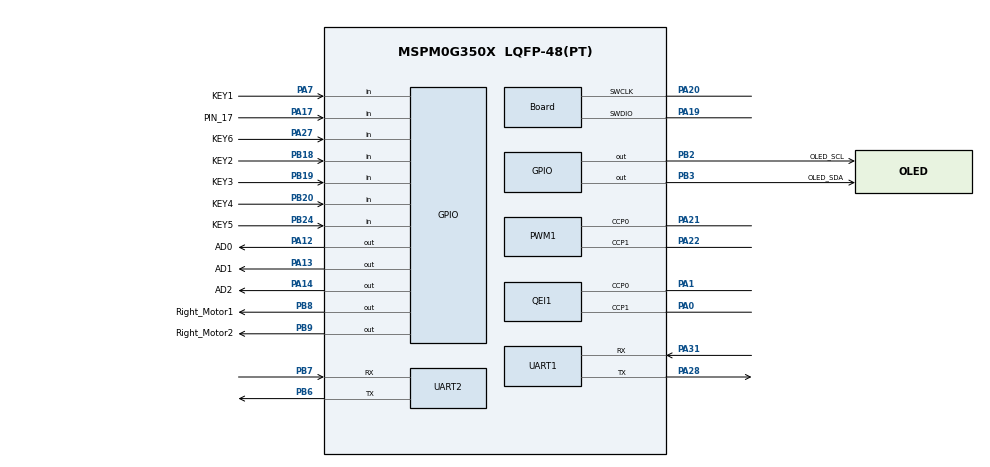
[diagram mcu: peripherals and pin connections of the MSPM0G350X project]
/**
 * @cliArgs --device "MSPM0G350X" --package "LQFP-48(PT)" --part "Default" --product "mspm0_sdk@1.30.00.03"
 * @versions {"tool":"1.19.0+3426"}
 */

/**
 * Import the modules used in this configuration.
 */
const ADC12         = scripting.addModule("/ti/driverlib/ADC12", {}, false);
const ADC121        = ADC12.addInstance();
const GPIO          = scripting.addModule("/ti/driverlib/GPIO", {}, false);
const GPIO1         = GPIO.addInstance();
const GPIO2         = GPIO.addInstance();
const GPIO3         = GPIO.addInstance();
const GPIO4         = GPIO.addInstance();
const GPIO5         = GPIO.addInstance();
const GPIO6         = GPIO.addInstance();
const PWM           = scripting.addModule("/ti/driverlib/PWM", {}, false);
const PWM1          = PWM.addInstance();
const QEI           = scripting.addModule("/ti/driverlib/QEI", {}, false);
const QEI1          = QEI.addInstance();
const SYSCTL        = scripting.addModule("/ti/driverlib/SYSCTL");
const SYSTICK       = scripting.addModule("/ti/driverlib/SYSTICK");
const TIMER         = scripting.addModule("/ti/driverlib/TIMER", {}, false);
const TIMER1        = TIMER.addInstance();
const UART          = scripting.addModule("/ti/driverlib/UART", {}, false);
const UART1         = UART.addInstance();
const UART2         = UART.addInstance();
const UART3         = UART.addInstance();
const UART4         = UART.addInstance();
const ProjectConfig = scripting.addModule("/ti/project_config/ProjectConfig");

/**
 * Write custom configuration values to the imported modules.
 */
const gate7  = system.clockTree["MFCLKGATE"];
gate7.enable = true;

ADC121.sampClkDiv                        = "DL_ADC12_CLOCK_DIVIDE_8";
ADC121.repeatMode                        = true;
ADC121.powerDownMode                     = "DL_ADC12_POWER_DOWN_MODE_MANUAL";
ADC121.$name                             = "ADC1";
ADC121.adcMem0_name                      = "ADC_Channel0";
ADC121.peripheral.$assign                = "ADC1";
ADC121.peripheral.adcPin0.$assign        = "PA15";
ADC121.adcPin0Config.hideOutputInversion = scripting.forceWrite(false);
ADC121.adcPin0Config.$name               = "ti_driverlib_gpio_GPIOPinGeneric2";

const Board                       = scripting.addModule("/ti/driverlib/Board", {}, false);
Board.peripheral.$assign          = "DEBUGSS";
Board.peripheral.swclkPin.$assign = "PA20";
Board.peripheral.swdioPin.$assign = "PA19";

GPIO1.$name                              = "KEY";
GPIO1.associatedPins.create(6);
GPIO1.associatedPins[0].$name            = "KEY1";
GPIO1.associatedPins[0].direction        = "INPUT";
GPIO1.associatedPins[0].internalResistor = "PULL_UP";
GPIO1.associatedPins[0].assignedPort     = "PORTA";
GPIO1.associatedPins[0].assignedPin      = "7";
GPIO1.associatedPins[0].pin.$assign      = "PA7";
GPIO1.associatedPins[1].$name            = "KEY2";
GPIO1.associatedPins[1].direction        = "INPUT";
GPIO1.associatedPins[1].assignedPort     = "PORTB";
GPIO1.associatedPins[1].internalResistor = "PULL_UP";
GPIO1.associatedPins[1].assignedPin      = "18";
GPIO1.associatedPins[1].pin.$assign      = "PB18";
GPIO1.associatedPins[2].$name            = "KEY3";
GPIO1.associatedPins[2].direction        = "INPUT";
GPIO1.associatedPins[2].assignedPort     = "PORTB";
GPIO1.associatedPins[2].internalResistor = "PULL_UP";
GPIO1.associatedPins[2].assignedPin      = "19";
GPIO1.associatedPins[2].pin.$assign      = "PB19";
GPIO1.associatedPins[3].$name            = "KEY4";
GPIO1.associatedPins[3].direction        = "INPUT";
GPIO1.associatedPins[3].assignedPort     = "PORTB";
GPIO1.associatedPins[3].assignedPin      = "20";
GPIO1.associatedPins[3].pin.$assign      = "PB20";
GPIO1.associatedPins[4].$name            = "KEY5";
GPIO1.associatedPins[4].direction        = "INPUT";
GPIO1.associatedPins[4].assignedPort     = "PORTB";
GPIO1.associatedPins[4].assignedPin      = "24";
GPIO1.associatedPins[4].pin.$assign      = "PB24";
GPIO1.associatedPins[5].$name            = "KEY6";
GPIO1.associatedPins[5].direction        = "INPUT";
GPIO1.associatedPins[5].assignedPort     = "PORTA";
GPIO1.associatedPins[5].assignedPin      = "27";
GPIO1.associatedPins[5].pin.$assign      = "PA27";

GPIO2.$name                          = "Motor";
GPIO2.associatedPins.create(4);
GPIO2.associatedPins[0].assignedPort = "PORTA";
GPIO2.associatedPins[0].assignedPin  = "8";
GPIO2.associatedPins[0].$name        = "Left_Motor1";
GPIO2.associatedPins[1].assignedPort = "PORTA";
GPIO2.associatedPins[1].assignedPin  = "9";
GPIO2.associatedPins[1].$name        = "Left_Motor2";
GPIO2.associatedPins[2].$name        = "Right_Motor1";
GPIO2.associatedPins[2].assignedPort = "PORTB";
GPIO2.associatedPins[2].assignedPin  = "8";
GPIO2.associatedPins[2].pin.$assign  = "PB8";
GPIO2.associatedPins[3].$name        = "Right_Motor2";
GPIO2.associatedPins[3].assignedPort = "PORTB";
GPIO2.associatedPins[3].assignedPin  = "9";
GPIO2.associatedPins[3].pin.$assign  = "PB9";

GPIO3.$name                          = "OLED";
GPIO3.associatedPins.create(2);
GPIO3.associatedPins[0].$name        = "OLED_SCL";
GPIO3.associatedPins[0].initialValue = "SET";
GPIO3.associatedPins[0].assignedPort = "PORTB";
GPIO3.associatedPins[0].assignedPin  = "2";
GPIO3.associatedPins[0].pin.$assign  = "PB2";
GPIO3.associatedPins[1].$name        = "OLED_SDA";
GPIO3.associatedPins[1].initialValue = "SET";
GPIO3.associatedPins[1].assignedPort = "PORTB";
GPIO3.associatedPins[1].assignedPin  = "3";
GPIO3.associatedPins[1].pin.$assign  = "PB3";

GPIO4.$name                         = "GWHD";
GPIO4.associatedPins.create(3);
GPIO4.associatedPins[0].$name       = "AD0";
GPIO4.associatedPins[0].pin.$assign = "PA12";
GPIO4.associatedPins[1].$name       = "AD1";
GPIO4.associatedPins[1].pin.$assign = "PA13";
GPIO4.associatedPins[2].$name       = "AD2";
GPIO4.associatedPins[2].pin.$assign = "PA14";

GPIO5.port                          = "PORTA";
GPIO5.$name                         = "OPENMV";
GPIO5.associatedPins[0].direction   = "INPUT";
GPIO5.associatedPins[0].assignedPin = "2";
GPIO5.associatedPins[0].$name       = "PIN_2";

GPIO6.$name                              = "HD";
GPIO6.port                               = "PORTA";
GPIO6.associatedPins.create(2);
GPIO6.associatedPins[0].$name            = "PIN_18";
GPIO6.associatedPins[0].direction        = "INPUT";
GPIO6.associatedPins[0].internalResistor = "PULL_UP";
GPIO6.associatedPins[0].assignedPin      = "18";
GPIO6.associatedPins[1].$name            = "PIN_17";
GPIO6.associatedPins[1].direction        = "INPUT";
GPIO6.associatedPins[1].internalResistor = "PULL_UP";
GPIO6.associatedPins[1].assignedPin      = "17";
GPIO6.associatedPins[1].pin.$assign      = "PA17";

PWM1.clockPrescale                      = 32;
PWM1.timerStartTimer                    = true;
PWM1.pwmMode                            = "EDGE_ALIGN_UP";
PWM1.$name                              = "PWM_Motor";
PWM1.peripheral.$assign                 = "TIMG6";
PWM1.peripheral.ccp0Pin.$assign         = "PA21";
PWM1.peripheral.ccp1Pin.$assign         = "PA22";
PWM1.PWM_CHANNEL_0.$name                = "ti_driverlib_pwm_PWMTimerCC0";
PWM1.PWM_CHANNEL_0.dutyCycle            = 100;
PWM1.PWM_CHANNEL_1.$name                = "ti_driverlib_pwm_PWMTimerCC1";
PWM1.PWM_CHANNEL_1.dutyCycle            = 100;
PWM1.ccp0PinConfig.direction            = scripting.forceWrite("OUTPUT");
PWM1.ccp0PinConfig.hideOutputInversion  = scripting.forceWrite(false);
PWM1.ccp0PinConfig.onlyInternalResistor = scripting.forceWrite(false);
PWM1.ccp0PinConfig.passedPeripheralType = scripting.forceWrite("Digital");
PWM1.ccp0PinConfig.$name                = "ti_driverlib_gpio_GPIOPinGeneric0";
PWM1.ccp1PinConfig.direction            = scripting.forceWrite("OUTPUT");
PWM1.ccp1PinConfig.hideOutputInversion  = scripting.forceWrite(false);
PWM1.ccp1PinConfig.onlyInternalResistor = scripting.forceWrite(false);
PWM1.ccp1PinConfig.passedPeripheralType = scripting.forceWrite("Digital");
PWM1.ccp1PinConfig.$name                = "ti_driverlib_gpio_GPIOPinGeneric1";

QEI1.$name                              = "ENCODER1";
QEI1.timerStartTimer                    = true;
QEI1.peripheral.ccp0Pin.$assign         = "PA1";
QEI1.peripheral.ccp1Pin.$assign         = "PA0";
QEI1.ccp0PinConfig.hideOutputInversion  = scripting.forceWrite(false);
QEI1.ccp0PinConfig.onlyInternalResistor = scripting.forceWrite(false);
QEI1.ccp0PinConfig.passedPeripheralType = scripting.forceWrite("Digital");
QEI1.ccp0PinConfig.$name                = "ti_driverlib_gpio_GPIOPinGeneric11";
QEI1.ccp1PinConfig.hideOutputInversion  = scripting.forceWrite(false);
QEI1.ccp1PinConfig.onlyInternalResistor = scripting.forceWrite(false);
QEI1.ccp1PinConfig.passedPeripheralType = scripting.forceWrite("Digital");
QEI1.ccp1PinConfig.$name                = "ti_driverlib_gpio_GPIOPinGeneric12";

SYSCTL.forceDefaultClkConfig = true;
SYSCTL.clockTreeEn           = true;

SYSTICK.interruptPriority = "0";
SYSTICK.periodEnable      = true;
SYSTICK.systickEnable     = true;
SYSTICK.period            = 32;

TIMER1.$name              = "TIMER_0";
TIMER1.timerClkPrescale   = 32;
TIMER1.timerPeriod        = "1 ms";
TIMER1.timerStartTimer    = true;
TIMER1.interrupts         = ["ZERO"];
TIMER1.timerMode          = "PERIODIC";
TIMER1.interruptPriority  = "3";
TIMER1.peripheral.$assign = "TIMA0";

UART1.$name                    = "UART_0";
UART1.uartClkSrc               = "MFCLK";
UART1.enableFIFO               = true;
UART1.enabledInterrupts        = ["RX"];
UART1.targetBaudRate           = 115200;
UART1.peripheral.$assign       = "UART0";
UART1.peripheral.rxPin.$assign = "PA31";
UART1.peripheral.txPin.$assign = "PA28";
UART1.txPinConfig.$name        = "ti_driverlib_gpio_GPIOPinGeneric3";
UART1.rxPinConfig.$name        = "ti_driverlib_gpio_GPIOPinGeneric4";

UART2.$name                    = "UART_1";
UART2.uartClkSrc               = "MFCLK";
UART2.targetBaudRate           = 115200;
UART2.enableFIFO               = true;
UART2.enabledInterrupts        = ["FRAMING_ERROR","OVERRUN_ERROR","PARITY_ERROR","RX","RX_TIMEOUT_ERROR"];
UART2.peripheral.rxPin.$assign = "PB7";
UART2.peripheral.txPin.$assign = "PB6";
UART2.txPinConfig.$name        = "ti_driverlib_gpio_GPIOPinGeneric5";
UART2.rxPinConfig.$name        = "ti_driverlib_gpio_GPIOPinGeneric6";

UART3.$name             = "UART_2";
UART3.uartClkSrc        = "MFCLK";
UART3.enableFIFO        = true;
UART3.enabledInterrupts = ["FRAMING_ERROR","OVERRUN_ERROR","PARITY_ERROR","RX","RX_TIMEOUT_ERROR"];
UART3.txPinConfig.$name = "ti_driverlib_gpio_GPIOPinGeneric7";
UART3.rxPinConfig.$name = "ti_driverlib_gpio_GPIOPinGeneric8";

UART4.$name              = "UART_3";
UART4.uartClkSrc         = "MFCLK";
UART4.targetBaudRate     = 115200;
UART4.enableFIFO         = true;
UART4.enabledInterrupts  = ["RX"];
UART4.peripheral.$assign = "UART3";
UART4.txPinConfig.$name  = "ti_driverlib_gpio_GPIOPinGeneric9";
UART4.rxPinConfig.$name  = "ti_driverlib_gpio_GPIOPinGeneric10";

ProjectConfig.deviceSpin = "MSPM0G3507";
scripting.suppress("Migrating requires going through the Switch Board or Device menu in the Device View section\\.", ProjectConfig, "deviceSpin");

/**
 * Pinmux solution for unlocked pins/peripherals. This ensures that minor changes to the automatic solver in a future
 * version of the tool will not impact the pinmux you originally saw.  These lines can be completely deleted in order to
 * re-solve from scratch.
 */
GPIO2.associatedPins[0].pin.$suggestSolution = "PA8";
GPIO2.associatedPins[1].pin.$suggestSolution = "PA9";
GPIO5.associatedPins[0].pin.$suggestSolution = "PA2";
GPIO6.associatedPins[0].pin.$suggestSolution = "PA18";
QEI1.peripheral.$suggestSolution             = "TIMG8";
UART2.peripheral.$suggestSolution            = "UART1";
UART3.peripheral.$suggestSolution            = "UART2";
UART3.peripheral.rxPin.$suggestSolution      = "PA24";
UART3.peripheral.txPin.$suggestSolution      = "PA23";
UART4.peripheral.rxPin.$suggestSolution      = "PA25";
UART4.peripheral.txPin.$suggestSolution      = "PA26";
